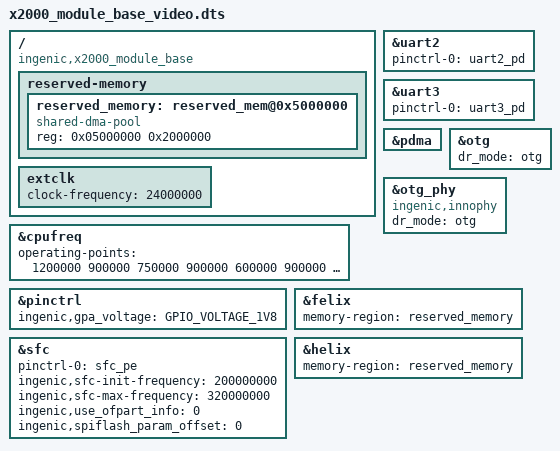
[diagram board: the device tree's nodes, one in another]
/dts-v1/;

#include <dt-bindings/input/input.h>
#include "x2000-v12.dtsi"
#include <dt-bindings/interrupt-controller/irq.h>
#include <generated/autoconf.h>

/ {
	compatible = "ingenic,x2000_module_base", "ingenic,x2000-v12";

	reserved-memory {
		#address-cells = <1>;
		#size-cells = <1>;
		ranges =<>;

		reserved_memory: reserved_mem@0x5000000{
		      compatible = "shared-dma-pool";
		      reg = <0x05000000 0x2000000>;
		};
	};
};

&uart2 {
	status = "okay";
	pinctrl-names = "default";
	pinctrl-0 = <&uart2_pd>;
};

&uart3 {
	status = "okay";
	pinctrl-names = "default";
	pinctrl-0 = <&uart3_pd>;
};

&cpufreq {
	status = "okay";
	operating-points = <
		/*KHZ uV */
		1200000	900000
		750000	900000
		600000	900000
		500000	900000
		400000	900000
		375000	900000
		300000	900000
		200000	900000
			>;

};

&pinctrl {
	ingenic,gpa_voltage = <GPIO_VOLTAGE_1V8>;
};

&pdma {
	status = "okay";
};

&sfc {
	status = "okay";
	pinctrl-names = "default";
	pinctrl-0 = <&sfc_pe>;
	ingenic,sfc-init-frequency = <200000000>;
	ingenic,sfc-max-frequency = <320000000>;
	ingenic,use_ofpart_info  = /bits/ 8 <0>;
	ingenic,spiflash_param_offset = <0>;


};

&otg {
	// g-use-dma;
	dr_mode = "otg";
	status = "okay";
};

&otg_phy {
	dr_mode = "otg";
	compatible = "ingenic,innophy", "syscon";
	status = "okay";
};

&felix {
	status = "okay";
	memory-region=<&reserved_memory>;
};

&helix {
	status = "okay";
	memory-region=<&reserved_memory>;
};

/ {

	extclk: extclk {
		clock-frequency = <24000000>;
	};

	};
